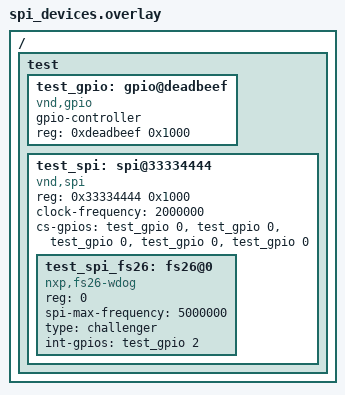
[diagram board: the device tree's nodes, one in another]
/*
 * Copyright (c) 2024 TOKITA Hiroshi
 * SPDX-License-Identifier: Apache-2.0
 */

/ {
	test {
		#address-cells = <1>;
		#size-cells = <1>;

		test_gpio: gpio@deadbeef {
			compatible = "vnd,gpio";
			gpio-controller;
			reg = <0xdeadbeef 0x1000>;
			#gpio-cells = <0x2>;
			status = "okay";
		};

		test_spi: spi@33334444 {
			#address-cells = <1>;
			#size-cells = <0>;
			compatible = "vnd,spi";
			reg = <0x33334444 0x1000>;
			status = "okay";
			clock-frequency = <2000000>;

			/* one entry for every devices at spi.dtsi */
			cs-gpios = <&test_gpio 0 0>,
				   <&test_gpio 0 0>,
				   <&test_gpio 0 0>,
				   <&test_gpio 0 0>,
				   <&test_gpio 0 0>;

			test_spi_fs26: fs26@0 {
				compatible = "nxp,fs26-wdog";
				reg = <0>;
				spi-max-frequency = <5000000>;
				type = "challenger";
				int-gpios = <&test_gpio 2 0>;
				status = "okay";
			};
		};
	};
};
